# CC3220SF register map
Vendor: Texas Instruments; Series: Wireless Connectivity MCU; File version: 1
CPU: CM4 r1p0, little endian, no MPU, no FPU, 8 interrupt priority bits
Registers are 32-bit, read-write, reset 0x0 unless marked. A register's access mark holds for its fields unless they carry their own. Offsets are from the block's base; [hi:lo] are bit positions; {n}, {i} and the like mark numbered series.

## GPRCM
Base 0x4402D000
0x00 APPS_SOFT_RESET
0x04 APPS_LPDS_WAKEUP_CFG
  [7:0] APPS_LPDS_WAKEUP_CFG — Mask for LPDS Wakeup interrupt : [7] - Host IRQ from NWP [6] - NWP_LPDS_Wake_irq (TRUE_LPDS) [5] - NWP Wake-request to APPS [4] - GPIO [3:1] - Reserved [0] - LPDS Wakeup-timer
0x08 APPS_LPDS_WAKEUP_SRC
  [7:0] APPS_LPDS_WAKEUP_SRC — Indicates the cause for wakeup from LPDS : [7] - Host IRQ from NWP [6] - NWP_LPDS_Wake_irq (TRUE_LPDS) [5] - NWP Wake-request to APPS [4] - GPIO [3:1] - Reserved [0] - LPDS Wakeup-timer
0x0C APPS_RESET_CAUSE
  [7:0] APPS_RESET_CAUSE — Indicates the reset cause for APPS : "0000" - Wake from HIB/OFF mode; "0001" - Wake from LPDS ; "0010" - Reserved ; "0011" - Soft-reset0 (Only APPS Cortex-sysrstn is asserted); "0100" - Soft-reset1 (APPS Cortex-sysrstn and APPS peripherals are reset); "0101" - WDOG0 (APPS Cortex-sysrstn and APPS peripherals are reset); "0110" - MCU Soft-reset (APPS + NWP Cortex-sysrstn + Peripherals are reset); "0111" - Secure Init done (Indication that reset has happened after DevInit); "1000" - Dev Mode Patch Init done (During development mode, patch downloading and Cortex re-vectoring is completed)
0x10 APPS_LPDS_WAKETIME_OPP_CFG
0x18 APPS_SRAM_DSLP_CFG
  [19:0] APPS_SRAM_DSLP_CFG — Configuration of APPS Memories during Deep-sleep : 0 - SRAMs are OFF ; 1 - SRAMs are Retained. APPS SRAM Cluster information : [0] - 1st column in MEMSS (Applicable only when owned by APPS); [1] - 2nd column in MEMSS (Applicable only when owned by APPS); [2] - 3rd column in MEMSS (Applicable only when owned by APPS) ; [3] - 4th column in MEMSS (Applicable only when owned by APPS) ; [16] - MCU-PD - Apps cluster 0 (TBD); [19:18] - Reserved.
0x1C APPS_SRAM_LPDS_CFG
  [19:0] APPS_SRAM_LPDS_CFG — Configuration of APPS Memories during LPDS : 0 - SRAMs are OFF ; 1 - SRAMs are Retained. APPS SRAM Cluster information : [0] - 1st column in MEMSS (Applicable only when owned by APPS); [1] - 2nd column in MEMSS (Applicable only when owned by APPS); [2] - 3rd column in MEMSS (Applicable only when owned by APPS) ; [3] - 4th column in MEMSS (Applicable only when owned by APPS) ; [16] - MCU-PD - Apps cluster 0 (TBD); [19:18] - Reserved.
0x20 APPS_LPDS_WAKETIME_WAKE_CFG
0x100 TOP_DIE_ENABLE
  [11:8] TOP_DIE_PWR_PS
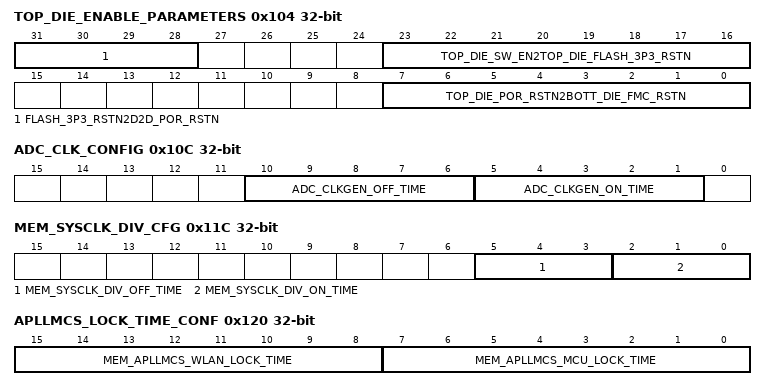
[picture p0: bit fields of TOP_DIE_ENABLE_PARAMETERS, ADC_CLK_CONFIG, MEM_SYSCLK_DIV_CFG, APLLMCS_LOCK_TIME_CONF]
0x104 TOP_DIE_ENABLE_PARAMETERS
  [31:28] FLASH_3P3_RSTN2D2D_POR_RSTN — Configuration (in slow_clks) for number of clks between Flash-3p3-rstn to D2D POR Resetn.
  [23:16] TOP_DIE_SW_EN2TOP_DIE_FLASH_3P3_RSTN — Configuration (in slow_clks) for number of clks between Top-die Switch-Enable and Top-die Flash 3p3 Reset removal
  [7:0] TOP_DIE_POR_RSTN2BOTT_DIE_FMC_RSTN — Configuration (in slow_clks) for number of clks between D2D POR Reset removal and bottom die FMC reset removal
0x108 MCU_GLOBAL_SOFT_RESET
0x10C ADC_CLK_CONFIG
  [10:6] ADC_CLKGEN_OFF_TIME — Configuration (in number of 38.4 MHz clks) for the OFF-Time in generation of ADC_CLK
  [5:1] ADC_CLKGEN_ON_TIME — Configuration (in number of 38.4 MHz clks) for the ON-Time in generation of ADC_CLK
0x110 APPS_GPIO_WAKE_CONF
  [1:0] APPS_GPIO_WAKE_CONF — "00" - Wake on Level0 on selected GPIO pin (GPIO is selected inside the HIB3p3 module); "01" - Wakeup on fall-edge of GPIO pin.
0x114 EN_NWP_BOOT_WO_DEVINIT
0x118 MEM_HCLK_DIV_CFG
  [2:0] MEM_HCLK_DIV_CFG — Division configuration for HCLKDIVOUT : "000" - Divide by 1 ; "001" - Divide by 2 ; "010" - Divide by 3 ; "011" - Divide by 4 ; "100" - Divide by 5 ; "101" - Divide by 6 ; "110" - Divide by 7 ; "111" - Divide by 8
0x11C MEM_SYSCLK_DIV_CFG
  [5:3] MEM_SYSCLK_DIV_OFF_TIME, [2:0] MEM_SYSCLK_DIV_ON_TIME
0x120 APLLMCS_LOCK_TIME_CONF
  [15:8] MEM_APLLMCS_WLAN_LOCK_TIME, [7:0] MEM_APLLMCS_MCU_LOCK_TIME
0x400 NWP_SOFT_RESET
0x404 NWP_LPDS_WAKEUP_CFG
  [7:0] NWP_LPDS_WAKEUP_CFG — Mask for LPDS Wakeup interrupt : 7 - WLAN Host Interrupt ; 6 - WLAN to NWP Wake request ; 5 - APPS to NWP Wake request; 4 - GPIO Wakeup ; 3 - Autonomous UART Wakeup ; 2 - SSDIO Wakeup ; 1 - Autonomous SPI Wakeup ; 0 - LPDS Wakeup-timer
0x408 NWP_LPDS_WAKEUP_SRC
  [7:0] NWP_LPDS_WAKEUP_SRC — Indicates the cause for NWP LPDS-Wakeup : 7 - WLAN Host Interrupt ; 6 - WLAN to NWP Wake request ; 5 - APPS to NWP Wake request; 4 - GPIO Wakeup ; 3 - Autonomous UART Wakeup ; 2 - SSDIO Wakeup ; 1 - Autonomous SPI Wakeup ; 0 - LPDS Wakeup-timer
0x40C NWP_RESET_CAUSE
  [7:0] NWP_RESET_CAUSE — Indicates the reset cause for NWP : "0000" - Wake from HIB/OFF mode; "0001" - Wake from LPDS ; "0010" - Reserved ; "0011" - Soft-reset0 (Only NWP Cortex-sysrstn is asserted); "0100" - Soft-reset1 (NWP Cortex-sysrstn and NWP peripherals are reset); "0101" - WDOG0 (NWP Cortex-sysrstn and NWP peripherals are reset); "0110" - MCU Soft-reset (APPS + NWP Cortex-sysrstn + Peripherals are reset); "0111" - SSDIO Function2 reset (Only Cortex-sysrstn is asserted) ; "1000" - Reset due to WDOG of APPS (NWP Cortex-sysrstn and NWP peripherals are reset);
0x410 NWP_LPDS_WAKETIME_OPP_CFG
0x418 NWP_SRAM_DSLP_CFG
  [19:0] NWP_SRAM_DSLP_CFG — Configuration of NWP Memories during DSLP : 0 - SRAMs are OFF ; 1 - SRAMs are Retained. NWP SRAM Cluster information : [2] - 3rd column in MEMSS (Applicable only when owned by NWP) ; [3] - 4th column in MEMSS (Applicable only when owned by NWP) ; [4] - 5th column in MEMSS (Applicable only when owned by NWP) ; [5] - 6th column in MEMSS (Applicable only when owned by NWP) ; [6] - 7th column in MEMSS (Applicable only when owned by NWP) ; [7] - 8th column in MEMSS (Applicable only when owned by NWP) ; [8] - 9th column in MEMSS (Applicable only when owned by NWP) ; [9] - 10th column in MEMSS (Applicable only when owned by NWP) ; [10] - 11th column in MEMSS (Applicable only when owned by NWP) ; [11] - 12th column in MEMSS (Applicable only when owned by NWP) ; [12] - 13th column in MEMSS (Applicable only when owned by NWP) ; [13] - 14th column in MEMSS (Applicable only when owned by NWP) ; [14] - 15th column in MEMSS (Applicable only when owned by NWP) ; [19:18] - Reserved.
0x41C NWP_SRAM_LPDS_CFG
  [19:0] NWP_SRAM_LPDS_CFG — Configuration of NWP Memories during LPDS : 0 - SRAMs are OFF ; 1 - SRAMs are Retained. NWP SRAM Cluster information : [2] - 3rd column in MEMSS (Applicable only when owned by NWP) ; [3] - 4th column in MEMSS (Applicable only when owned by NWP) ; [4] - 5th column in MEMSS (Applicable only when owned by NWP) ; [5] - 6th column in MEMSS (Applicable only when owned by NWP) ; [6] - 7th column in MEMSS (Applicable only when owned by NWP) ; [7] - 8th column in MEMSS (Applicable only when owned by NWP) ; [8] - 9th column in MEMSS (Applicable only when owned by NWP) ; [9] - 10th column in MEMSS (Applicable only when owned by NWP) ; [10] - 11th column in MEMSS (Applicable only when owned by NWP) ; [11] - 12th column in MEMSS (Applicable only when owned by NWP) ; [12] - 13th column in MEMSS (Applicable only when owned by NWP) ; [13] - 14th column in MEMSS (Applicable only when owned by NWP) ; [14] - 15th column in MEMSS (Applicable only when owned by NWP) ; [19:18] - Reserved.
0x420 NWP_LPDS_WAKETIME_WAKE_CFG
0x424 NWP_AUTONMS_SPI_MASTER_SEL
  [31:17] F
0x428 NWP_AUTONMS_SPI_IDLE_REQ
0x42C WLAN_TO_NWP_WAKE_REQUEST
0x430 NWP_TO_WLAN_WAKE_REQUEST
0x434 NWP_GPIO_WAKE_CONF
  [1:0] NWP_GPIO_WAKE_CONF — "00" - Wakeup on level0 of the selected GPIO (GPIO gets selected inside HIB3P3-module); "01" - Wakeup on fall-edge of selected GPIO.
0x438 EFUSE_READ_REG12
0x448 DIEID_READ_REG5
0x44C DIEID_READ_REG6
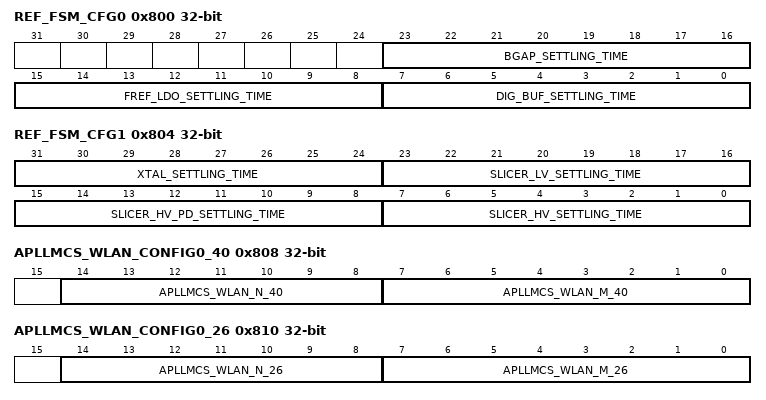
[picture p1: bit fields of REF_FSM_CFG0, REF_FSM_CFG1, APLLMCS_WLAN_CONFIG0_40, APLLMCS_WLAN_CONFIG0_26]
0x800 REF_FSM_CFG0
  [23:16] BGAP_SETTLING_TIME — ANA-BGAP Settling time (In number of slow_clks)
  [15:8] FREF_LDO_SETTLING_TIME — Slicer LDO settling time (In number of slow clks)
  [7:0] DIG_BUF_SETTLING_TIME — Dig-buffer settling time (In number of slow clks)
0x804 REF_FSM_CFG1
  [31:24] XTAL_SETTLING_TIME — XTAL settling time (In number of slow clks)
  [23:16] SLICER_LV_SETTLING_TIME — LV Slicer settling time
  [15:8] SLICER_HV_PD_SETTLING_TIME — HV Slicer Pull-down settling time
  [7:0] SLICER_HV_SETTLING_TIME — HV Slicer settling time
0x808 APLLMCS_WLAN_CONFIG0_40
  [14:8] APLLMCS_WLAN_N_40 — Configuration for WLAN APLLMCS - N[6:0], if the XTAL frequency is 40 MHz (Selected by efuse)
  [7:0] APLLMCS_WLAN_M_40 — Configuration for WLAN APLLMCS - M[7:0], if the XTAL frequency is 40 MHz (Selected by efuse)
0x80C APLLMCS_WLAN_CONFIG1_40
  [2:0] APLLMCS_SELINPFREQ_40 — Configuration for WLAN APLLMCS - Selinpfreq, if the XTAL frequency is 40 MHz (Selected by Efuse)
0x810 APLLMCS_WLAN_CONFIG0_26
  [14:8] APLLMCS_WLAN_N_26 — Configuration for WLAN APLLMCS - N[6:0], if the XTAL frequency is 26 MHz (Selected by efuse)
  [7:0] APLLMCS_WLAN_M_26 — Configuration for WLAN APLLMCS - M[7:0], if the XTAL frequency is 26 MHz (Selected by efuse)
0x814 APLLMCS_WLAN_CONFIG1_26
  [2:0] APLLMCS_SELINPFREQ_26 — Configuration for WLAN APLLMCS - Selinpfreq, if the XTAL frequency is 26 MHz (Selected by Efuse)
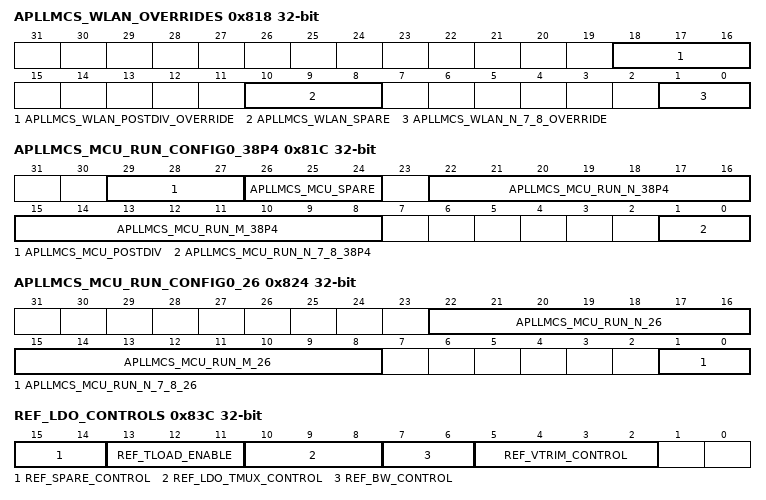
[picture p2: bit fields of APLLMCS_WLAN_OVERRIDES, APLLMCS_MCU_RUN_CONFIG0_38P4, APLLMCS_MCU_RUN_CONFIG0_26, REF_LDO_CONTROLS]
0x818 APLLMCS_WLAN_OVERRIDES
  [18:16] APLLMCS_WLAN_POSTDIV_OVERRIDE
  [10:8] APLLMCS_WLAN_SPARE
  [1:0] APLLMCS_WLAN_N_7_8_OVERRIDE — Override value for WLAN_APLLMCS_N[8:7] bits. Applicable only when bit [1] is set to 1. (Else controlled from WTOP)
0x81C APLLMCS_MCU_RUN_CONFIG0_38P4
  [29:27] APLLMCS_MCU_POSTDIV
  [26:24] APLLMCS_MCU_SPARE
  [22:16] APLLMCS_MCU_RUN_N_38P4 — Configuration for MCU-APLLMCS : N during RUN mode. Selected if the XTAL frequency is 38.4 MHz (from Efuse)
  [15:8] APLLMCS_MCU_RUN_M_38P4 — Configuration for MCU-APLLMCS : M during RUN mode. Selected if the XTAL frequency is 38.4 MHz (from Efuse)
  [1:0] APLLMCS_MCU_RUN_N_7_8_38P4 — Configuration for MCU-APLLMCS : N[8:7] during RUN mode. Selected if the XTAL frequency is 38.4 MHz (From Efuse)
0x820 APLLMCS_MCU_RUN_CONFIG1_38P4
  [2:0] APLLMCS_MCU_RUN_SELINPFREQ_38P4 — Configuration for MCU-APLLMCS : SELINPFREQ during RUN mode. Selected if the XTAL frequency is 38.4 MHz (from Efuse)
0x824 APLLMCS_MCU_RUN_CONFIG0_26
  [22:16] APLLMCS_MCU_RUN_N_26 — Configuration for MCU-APLLMCS : N during RUN mode. Selected if the XTAL frequency is 26 MHz (from Efuse)
  [15:8] APLLMCS_MCU_RUN_M_26 — Configuration for MCU-APLLMCS : M during RUN mode. Selected if the XTAL frequency is 26 MHz (from Efuse)
  [1:0] APLLMCS_MCU_RUN_N_7_8_26 — Configuration for MCU-APLLMCS : N[8:7] during RUN mode. Selected if the XTAL frequency is 26 MHz (From Efuse)
0x828 APLLMCS_MCU_RUN_CONFIG1_26
  [2:0] APLLMCS_MCU_RUN_SELINPFREQ_26 — Configuration for MCU-APLLMCS : SELINPFREQ during RUN mode. Selected if the XTAL frequency is 26 MHz (from Efuse)
0x82C SPARE_RW0
0x830 SPARE_RW1
0x834 APLLMCS_MCU_OVERRIDES
  [2:1] SYSCLK_SRC_OVERRIDE — Override for sysclk src (applicable only if bit [0] is set to 1. "00"- SLOW_CLK "01"- XTAL_CLK "10"- PLL_CLK
0x838 SYSCLK_SWITCH_STATUS
0x83C REF_LDO_CONTROLS
  [15:14] REF_SPARE_CONTROL — Spare bits for REF_CTRL_FSM. Reaches directly on port TOP_PM_REG2[15:14] of gprcm.
  [13:11] REF_TLOAD_ENABLE — REF TLOAD Enable. Reaches directly on port TOP_PM_REG2[13:11] of gprcm.
  [10:8] REF_LDO_TMUX_CONTROL — REF_LDO Test-mux control. Reaches directly on port TOP_PM_REG2[10:8] of gprcm.
  [7:6] REF_BW_CONTROL — REF BW Control. Reaches directly on port TOP_PM_REG2[7:6] of gprcm.
  [5:2] REF_VTRIM_CONTROL — REF VTRIM Control. Reaches directly on port TOP_PM_REG2[5:2] of gprcm.
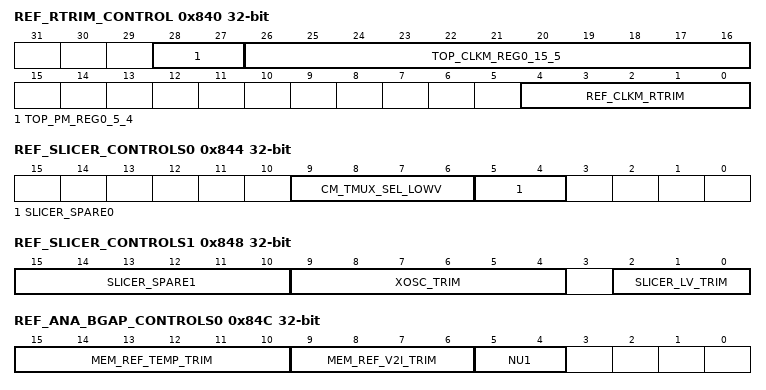
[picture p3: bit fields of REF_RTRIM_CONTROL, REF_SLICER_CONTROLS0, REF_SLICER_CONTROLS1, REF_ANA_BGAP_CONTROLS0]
0x840 REF_RTRIM_CONTROL
  [28:27] TOP_PM_REG0_5_4 — This is [5:4] bits of TOP_PM_REG0
  [26:16] TOP_CLKM_REG0_15_5 — This is [15:5] bits of TOP_CLKM_REG0
  [4:0] REF_CLKM_RTRIM — CLKM_TRIM Override. Applicable when efuse_done = 0 or bit[8] is set to 1.
0x844 REF_SLICER_CONTROLS0
  [9:6] CM_TMUX_SEL_LOWV — CM Test-mux select. Reaches on TOP_CLMM_REG1_IN[9:6] port of gprcm
  [5:4] SLICER_SPARE0 — Slicer spare0 control. Reaches on TOP_CLKM_REG1_IN[5:4] port of gprcm
0x848 REF_SLICER_CONTROLS1
  [15:10] SLICER_SPARE1 — Slicer spare1. Reaches on port TOP_CLKM_REG2_IN[15:10] of gprcm.
  [9:4] XOSC_TRIM — XOSC Trim. Reaches on port TOP_CLKM_REG2_IN[9:4] of gprcm
  [2:0] SLICER_LV_TRIM — LV Slicer trim. Reaches on port TOP_CLKM_REG2_IN[2:0] of gprcm.
0x84C REF_ANA_BGAP_CONTROLS0
  [15:10] MEM_REF_TEMP_TRIM — REF_TEMP_TRIM override. Applicable when bit [20] of this register set to 1. (or efc_done = 0) Note : Final REF_TEMP_TRIM reaches on port TOP_PM_REG0[15:10] of gprcm.
  [9:6] MEM_REF_V2I_TRIM — REF_V2I_TRIM Override. Applicable when bit [21] of this register set to 1 . (of efc_done = 0) Note : Final REF_V2I_TRIM reaches on port TOP_PM_REG0[9:6] of gprcm.
  [5:4] NU1
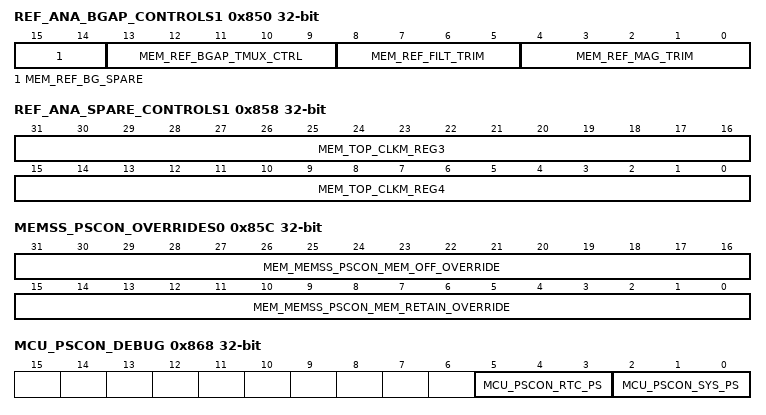
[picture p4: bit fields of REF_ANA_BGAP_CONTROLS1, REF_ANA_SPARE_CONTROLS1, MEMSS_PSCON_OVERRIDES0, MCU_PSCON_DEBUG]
0x850 REF_ANA_BGAP_CONTROLS1
  [15:14] MEM_REF_BG_SPARE — REF_BGAP_SPARE. Reaches on port TOP_PM_REG1[15:14] of gprcm.
  [13:9] MEM_REF_BGAP_TMUX_CTRL — REF_BGAP_TMUX_CTRL. Reaches on port TOP_PM_REG1[13:9] of gprcm.
  [8:5] MEM_REF_FILT_TRIM — REF_FILT_TRIM. Reaches on port TOP_PM_REG1[8:5] of gprcm.
  [4:0] MEM_REF_MAG_TRIM — REF_MAG_TRIM Override. Applicable when bit[22] of REF_ANA_BGAP_CONTROLS0 [0x084C] set to 1 (of efc_done = 0). Note : Final REF_MAG_TRIM reaches on port TOP_PM_REG1[4:0] of gprcm
0x854 REF_ANA_SPARE_CONTROLS0
  [15:0] MEM_TOP_PM_REG3 — Spare control. Reaches on TOP_PM_REG3 [15:0] of gprcm.
0x858 REF_ANA_SPARE_CONTROLS1
  [31:16] MEM_TOP_CLKM_REG3 — Spare control. Reaches on TOP_CLKM_REG3 [15:0] of gprcm.
  [15:0] MEM_TOP_CLKM_REG4 — Spare control. Reaches on TOP_CLKM_REG4 [15:0] of gprcm.
0x85C MEMSS_PSCON_OVERRIDES0
  [31:16] MEM_MEMSS_PSCON_MEM_OFF_OVERRIDE, [15:0] MEM_MEMSS_PSCON_MEM_RETAIN_OVERRIDE
0x860 MEMSS_PSCON_OVERRIDES1
0x864 PLL_REF_LOCK_OVERRIDES
0x868 MCU_PSCON_DEBUG
  [5:3] MCU_PSCON_RTC_PS — MCU_PSCON_RTC_ON = "0000"; MCU_PSCON_RTC_OFF = "0001"; MCU_PSCON_RTC_RET = "0010"; MCU_PSCON_RTC_OFF_TO_ON = "0011"; MCU_PSCON_RTC_RET_TO_ON = "0100"; MCU_PSCON_RTC_ON_TO_RET = "0101"; MCU_PSCON_RTC_ON_TO_OFF = "0110"; MCU_PSCON_RTC_RET_TO_ON_WAIT_OPP = "0111"; MCU_PSCON_RTC_OFF_TO_ON_WAIT_OPP = "1000";
  [2:0] MCU_PSCON_SYS_PS
0x86C MEMSS_PWR_PS
  [2:0] PWR_PS_MEMSS — MEMSS_PM_SLEEP = "000"; MEMSS_PM_WAIT_OPP = "010"; MEMSS_PM_ACTIVE = "011"; MEMSS_PM_SLEEP_TO_ACTIVE = "100"; MEMSS_PM_ACTIVE_TO_SLEEP = "101";
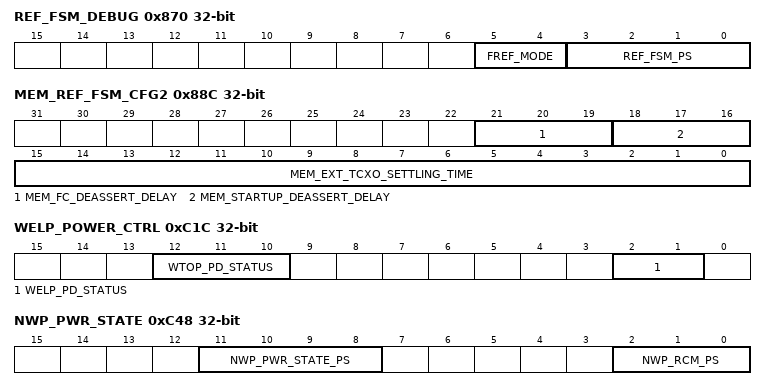
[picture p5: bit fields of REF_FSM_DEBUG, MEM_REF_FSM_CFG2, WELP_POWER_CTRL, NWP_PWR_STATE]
0x870 REF_FSM_DEBUG
  [5:4] FREF_MODE — 01 - HV Mode ; 10 - LV Mode ; 11 - XTAL Mode
  [3:0] REF_FSM_PS — constant FREF_CLK_OFF = "00000"; constant FREF_EN_BGAP = "00001"; constant FREF_EN_LDO = "00010"; constant FREF_EN_SLI_HV = "00011"; constant FREF_EN_SLI_HV_PD = "00100"; constant FREF_EN_DIG_BUF = "00101"; constant FREF_EN_OSC = "00110"; constant FREF_EN_SLI_LV = "00111"; constant FREF_EN_CLK_REQ = "01000"; constant FREF_CLK_VALID = "01001"; constant FREF_MODE_DET0 = "01010"; constant FREF_MODE_DET1 = "01011"; constant FREF_MODE_DET2 = "10010"; constant FREF_MODE_DET3 = "10011"; constant FREF_VALID = "01100"; constant FREF_VALID0 = "01101"; constant FREF_VALID1 = "01110"; constant FREF_VALID2 = "01111"; constant FREF_WAIT_EXT_TCXO0 = "10000"; constant FREF_WAIT_EXT_TCXO1 = "10001";
0x874 MEM_SYS_OPP_REQ_OVERRIDE
  [3:0] MEM_SYS_OPP_REQ_OVERRIDE — "0001" - RUN ; "0010" - DSLP ; "0100" - LPDS ; Others - NA
0x878 MEM_TESTCTRL_PD_OPP_CONFIG
0x87C MEM_WL_FAST_CLK_REQ_OVERRIDES
0x880 MEM_MCU_PD_MODE_REQ_OVERRIDES
0x884 MEM_MCSPI_SRAM_OFF_REQ_OVERRIDES
0x888 MEM_WLAN_APLLMCS_OVERRIDES
0x88C MEM_REF_FSM_CFG2
  [21:19] MEM_FC_DEASSERT_DELAY — Number of RTC clocks for keeping the FC_EN asserted high
  [18:16] MEM_STARTUP_DEASSERT_DELAY — Number of RTC clocks for keeping the STARTUP_EN asserted high
  [15:0] MEM_EXT_TCXO_SETTLING_TIME — Number of RTC clocks for waiting for clock to settle.
0xC10 TESTCTRL_POWER_CTRL
  [2:1] TESTCTRL_PD_STATUS
0xC14 SSDIO_POWER_CTRL
  [2:1] SSDIO_PD_STATUS — 1 - SSDIO-PD is ON ; 0 - SSDIO-PD is OFF
0xC18 MCSPI_N1_POWER_CTRL
  [2:1] MCSPI_N1_PD_STATUS — 1 - MCSPI_N1-PD is ON ; 0 - MCSPI_N1-PD if OFF
0xC1C WELP_POWER_CTRL
  [12:10] WTOP_PD_STATUS, [2:1] WELP_PD_STATUS
0xC20 WL_SDIO_POWER_CTRL
  [2:1] WL_SDIO_PD_STATUS
0xC24 WLAN_SRAM_ACTIVE_PWR_CFG
  [23:0] WLAN_SRAM_ACTIVE_PWR_CFG — SRAM (WTOP+DRP) state during Active-mode : 1 - SRAMs are ON ; 0 - SRAMs are OFF. Cluster information : [0] - 1st column of MEMSS (Applicable only when owned by WTOP/PHY) [1] - 2nd column of MEMSS (Applicable only when owned by WTOP/PHY) ; [2] - 3rd column of MEMSS (Applicable only when owned by WTOP/PHY) ; [3] - 4th column of MEMSS (Applicable only when owned by WTOP/PHY) ; [4] - 5th column of MEMSS (Applicable only when owned by WTOP/PHY) ; [5] - 6th column of MEMSS (Applicable only when owned by WTOP/PHY) ; [6] - 7th column of MEMSS (Applicable only when owned by WTOP/PHY) ; [7] - 8th column of MEMSS (Applicable only when owned by WTOP/PHY) ; [8] - 9th column of MEMSS (Applicable only when owned by WTOP/PHY) ; [9] - 10th column of MEMSS (Applicable only when owned by WTOP/PHY) ; [10] - 11th column of MEMSS (Applicable only when owned by WTOP/PHY) ; [11] - 12th column of MEMSS (Applicable only when owned by WTOP/PHY) ; [12] - 13th column of MEMSS (Applicable only when owned by WTOP/PHY) ; [13] - 14th column of MEMSS (Applicable only when owned by WTOP/PHY) ; [14] - 15th column of MEMSS (Applicable only when owned by WTOP/PHY) ; [15] - 16th column of MEMSS (Applicable only when owned by WTOP/PHY) ; [23:16] - Internal to WTOP Cluster
0xC28 WLAN_SRAM_SLEEP_PWR_CFG
  [23:0] WLAN_SRAM_SLEEP_PWR_CFG — SRAM (WTOP+DRP) state during Sleep-mode : 1 - SRAMs are RET ; 0 - SRAMs are OFF. Cluster information : [0] - 1st column of MEMSS (Applicable only when owned by WTOP/PHY) [1] - 2nd column of MEMSS (Applicable only when owned by WTOP/PHY) ; [2] - 3rd column of MEMSS (Applicable only when owned by WTOP/PHY) ; [3] - 4th column of MEMSS (Applicable only when owned by WTOP/PHY) ; [4] - 5th column of MEMSS (Applicable only when owned by WTOP/PHY) ; [5] - 6th column of MEMSS (Applicable only when owned by WTOP/PHY) ; [6] - 7th column of MEMSS (Applicable only when owned by WTOP/PHY) ; [7] - 8th column of MEMSS (Applicable only when owned by WTOP/PHY) ; [8] - 9th column of MEMSS (Applicable only when owned by WTOP/PHY) ; [9] - 10th column of MEMSS (Applicable only when owned by WTOP/PHY) ; [10] - 11th column of MEMSS (Applicable only when owned by WTOP/PHY) ; [11] - 12th column of MEMSS (Applicable only when owned by WTOP/PHY) ; [12] - 13th column of MEMSS (Applicable only when owned by WTOP/PHY) ; [13] - 14th column of MEMSS (Applicable only when owned by WTOP/PHY) ; [14] - 15th column of MEMSS (Applicable only when owned by WTOP/PHY) ; [15] - 16th column of MEMSS (Applicable only when owned by WTOP/PHY) ; [23:16] - Internal to WTOP Cluster
0xC30 APPS_SECURE_INIT_DONE
0xC34 APPS_DEV_MODE_INIT_DONE
0xC38 EN_APPS_REBOOT
0xC3C MEM_APPS_PERIPH_PRESENT
0xC40 MEM_NWP_PERIPH_PRESENT
0xC44 MEM_SHARED_PERIPH_PRESENT
0xC48 NWP_PWR_STATE
  [11:8] NWP_PWR_STATE_PS — "0000"- PORZ :- NWP is yet to be enabled by APPS during powerup (from HIB/OFF) ; "0011"- ACTIVE :- NWP is enabled, clocks and resets to NWP-SubSystem are enabled ; "0010"- LPDS :- NWP is in LPDS-mode ; Clocks and reset to NWP-SubSystem are gated ; "0101"- WAIT_FOR_OPP :- NWP is in transition from LPDS to ACTIVE, where it is waiting for OPP to be stable ; "1000"- WAKE_TIMER_OPP_REQ :- NWP is in transition from LPDS, where the wakeup cause is LPDS_Wake timer OTHERS : NA
  [2:0] NWP_RCM_PS — "000" - NWP_RUN : NWP is in RUN state (default) - Applicable only when NWP_PWR_STATE_PS = ACTIVE ; "001" - NWP_SLP : NWP is in SLEEP state (default) - Applicable only when NWP_PWR_STATE_PS = ACTIVE ; "010" - NWP_DSLP : NWP is in Deep-Sleep state (default) - Applicable only when NWP_PWR_STATE_PS = ACTIVE ; "011" - WAIT_FOR_ACTIVE : NWP is in transition from Deep-sleep to Run, where it is waiting for OPP to be stable ; "100" - WAIT_FOR_DSLP_TIMER_WAKE_REQ : NWP is in transition from Deep-sleep to Run, where the wakeup cause is deep-sleep wake-timer
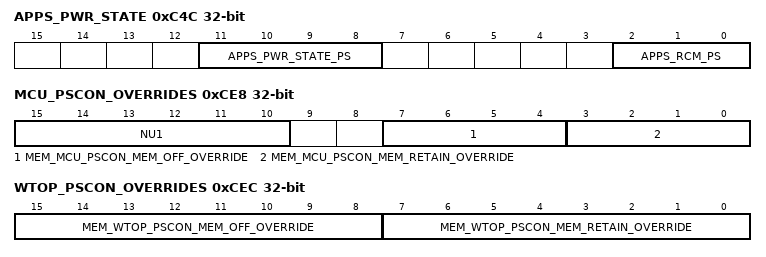
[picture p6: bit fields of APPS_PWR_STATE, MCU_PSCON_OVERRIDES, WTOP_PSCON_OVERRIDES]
0xC4C APPS_PWR_STATE
  [11:8] APPS_PWR_STATE_PS — "0000"- PORZ :- APPS is waiting for PLL_clock during powerup (from HIB/OFF) ; "0011"- ACTIVE :- APPS is enabled, clocks and resets to APPS-SubSystem are enabled ; APPS might be either in Secure or Un-secure mode during this state. "1001" - SECURE_MODE_LPDS :- While in ACTIVE (Secure-mode), APPS had to program the DevInit_done bit at the end, after which it enters into this state, where the reset to APPS will be asserted. From this state APPS might either re-boot itself or enter into LPDS depending upon whether the device is 3200 or 3100. "0010"- LPDS :- APPS is in LPDS-mode ; Clocks and reset to APPS-SubSystem are gated ; "0101"- WAIT_FOR_OPP :- APPS is in transition from LPDS to ACTIVE, where it is waiting for OPP to be stable ; "1000" - WAKE_TIMER_OPP_REQ : APPS is in transition from LPDS, where the wakeup cause is LPDS_Wake timer ; "1010" - WAIT_FOR_PATCH_INIT : APPS enters into this state during development-mode #3 (SOP = 3), where it is waiting for patch download to complete and 0x4 hack is programmed. OTHERS : NA
  [2:0] APPS_RCM_PS — "000" - APPS_RUN : APPS is in RUN state (default) - Applicable only when APPS_PWR_STATE_PS = ACTIVE ; "001" - APPS_SLP : APPS is in SLEEP state (default) - Applicable only when APPS_PWR_STATE_PS = ACTIVE ; "010" - APPS_DSLP : APPS is in Deep-Sleep state (default) - Applicable only when APPS_PWR_STATE_PS = ACTIVE ; "011" - WAIT_FOR_ACTIVE : APPS is in transition from Deep-sleep to Run, where it is waiting for OPP to be stable ; "100" - WAIT_FOR_DSLP_TIMER_WAKE_REQ : APPS is in transition from Deep-sleep to Run, where the wakeup cause is deep-sleep wake-timer
0xC50 MCU_PWR_STATE
  [4:0] MCU_OPP_PS
0xC54 WTOP_PM_PS
  [2:0] WTOP_PM_PS — "011" - WTOP_PM_ACTIVE (Default) :- WTOP_Pd is in ACTIVE mode; "100" - WTOP_PM_ACTIVE_TO_SLEEP :- WTOP_Pd is in transition from ACTIVE to SLEEP ; "000" - WTOP_PM_SLEEP : WTOP-Pd is in Sleep-state ; "100" - WTOP_PM_SLEEP_TO_ACTIVE : WTOP_Pd is in transition from SLEEP to ACTIVE ; "000" - WTOP_PM_WAIT_FOR_OPP : Wait for OPP to be stable ;
0xC58 WTOP_PD_RESETZ_OVERRIDE_REG
0xC5C WELP_PD_RESETZ_OVERRIDE_REG
0xC60 WL_SDIO_PD_RESETZ_OVERRIDE_REG
0xC64 SSDIO_PD_RESETZ_OVERRIDE_REG
0xC68 MCSPI_N1_PD_RESETZ_OVERRIDE_REG
0xC6C TESTCTRL_PD_RESETZ_OVERRIDE_REG
0xC70 MCU_PD_RESETZ_OVERRIDE_REG
{0xC78+4i} EFUSE_READ_REG{i} (i=0..3)
0xC88 WTOP_MEM_RET_CFG
0xC8C COEX_CLK_SWALLOW_CFG0
  [22:0] Q_FACTOR
0xC90 COEX_CLK_SWALLOW_CFG1
  [19:0] P_FACTOR
0xC94 COEX_CLK_SWALLOW_CFG2
  [4:3] CONSECUTIVE_SWALLOW
0xC98 COEX_CLK_SWALLOW_ENABLE
0xC9C DCDC_CLK_GEN_CONFIG
{0xC90+4i} EFUSE_READ_REG{i} (i=4..11)
{0xCC0+4i} DIEID_READ_REG{i} (i=0..4)
0xCD4 APPS_SS_OVERRIDES
0xCD8 NWP_SS_OVERRIDES
0xCDC SHARED_SS_OVERRIDES
0xCE0 IDMEM_CORE_RST_OVERRIDES
0xCE4 TOP_DIE_FSM_OVERRIDES
0xCE8 MCU_PSCON_OVERRIDES
  [15:10] NU1, [7:4] MEM_MCU_PSCON_MEM_OFF_OVERRIDE, [3:0] MEM_MCU_PSCON_MEM_RETAIN_OVERRIDE
0xCEC WTOP_PSCON_OVERRIDES
  [15:8] MEM_WTOP_PSCON_MEM_OFF_OVERRIDE, [7:0] MEM_WTOP_PSCON_MEM_RETAIN_OVERRIDE
0xCF0 WELP_PSCON_OVERRIDES
0xCF4 WL_SDIO_PSCON_OVERRIDES
0xCF8 MCSPI_PSCON_OVERRIDES
0xCFC SSDIO_PSCON_OVERRIDES
